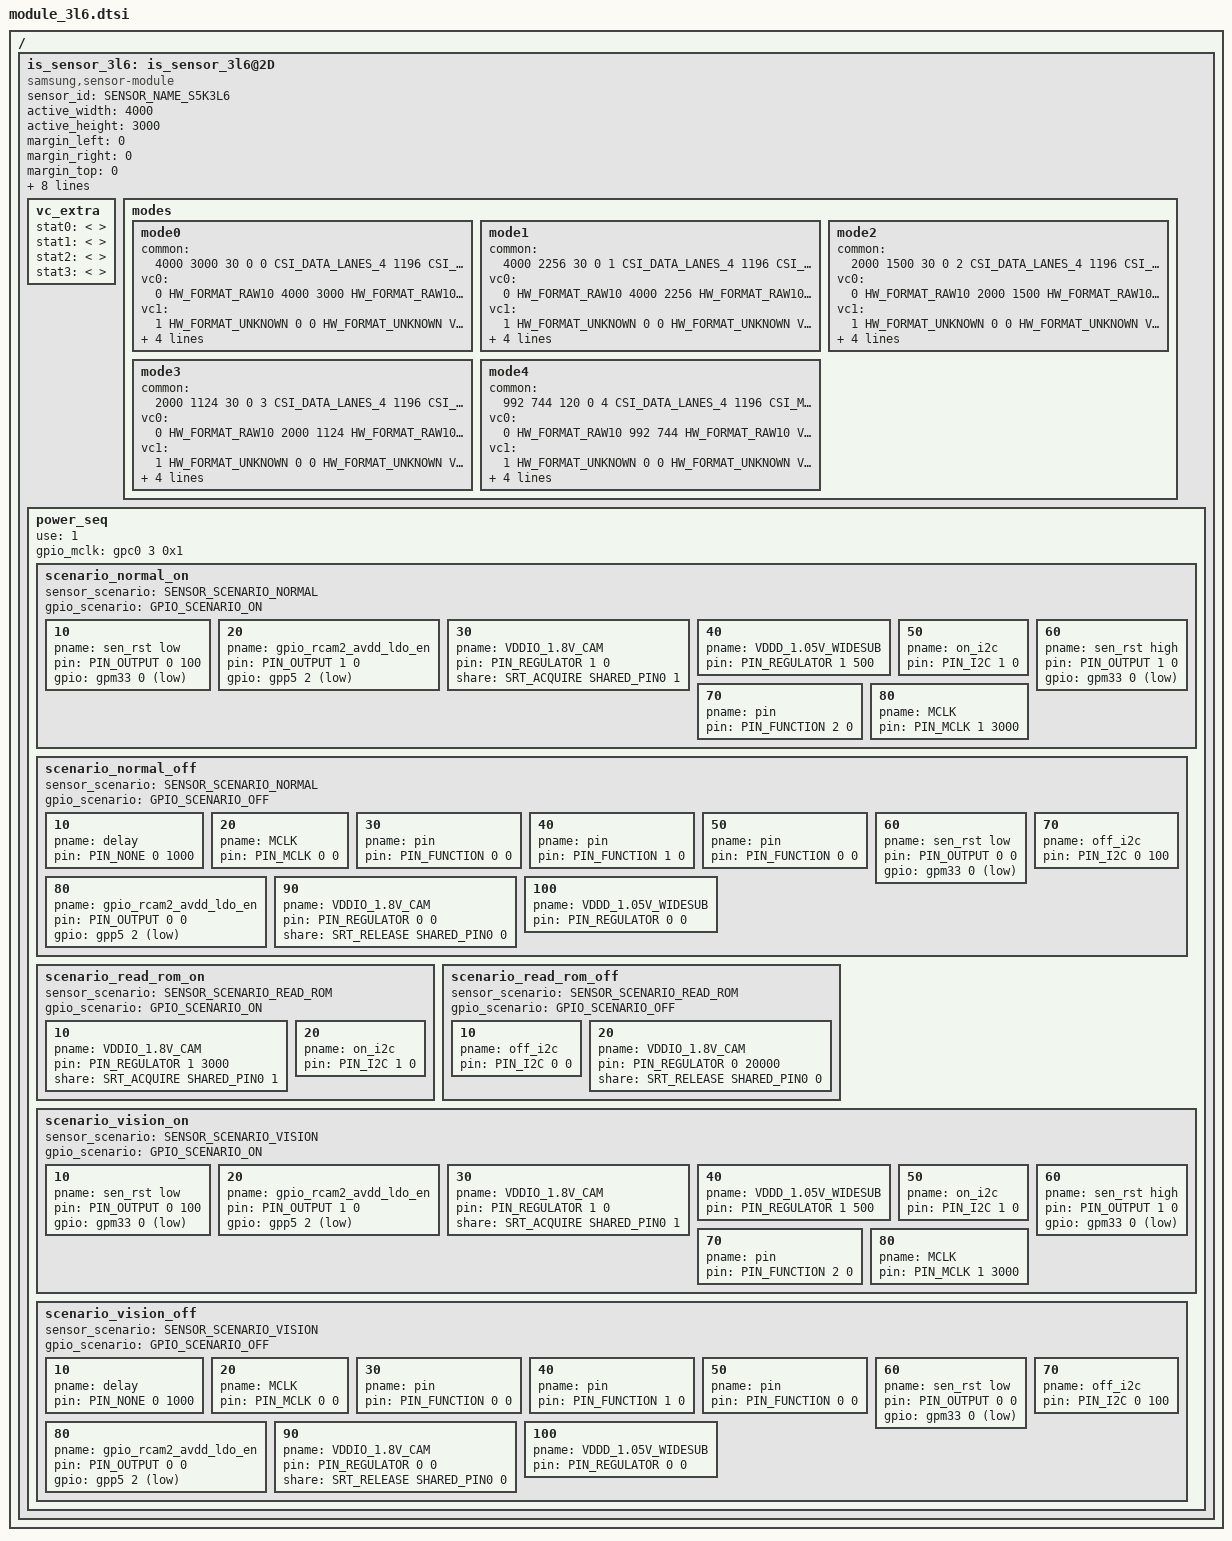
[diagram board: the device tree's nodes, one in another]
/*
 * SAMSUNG EXYNOSxxxx board camera device tree source
 *
 * Copyright (c) 2019 Samsung Electronics Co., Ltd.
 *		http://www.samsung.com
 *
 * This program is free software; you can redistribute it and/or modify
 * it under the terms of the GNU General Public License version 2 as
 * published by the Free Software Foundation.
 */

#include <dt-bindings/camera/exynos_is_dt.h>

/ {
	fragment@camera {
		target-path = "/";
		__overlay__ {
			is_sensor_3l6: is_sensor_3l6@2D {
				compatible = "samsung,sensor-module";

				/* common */
				sensor_id = <SENSOR_NAME_S5K3L6>;
				active_width = <4000>;
				active_height = <3000>;
				margin_left = <0>;
				margin_right = <0>;
				margin_top = <0>;
				margin_bottom = <0>;
				max_framerate = <120>;
				bitwidth = <10>;
				use_retention_mode = <SENSOR_RETENTION_UNSUPPORTED>;
				sensor_maker = "SLSI";
				sensor_name = "S5K3L6";
				setfile_name = "setfile_3l6.bin";

				status = "okay";

				vc_extra {
					/* ex) statX = <stat_type, sensor_mode, max_width, max_height, max_element> */
					stat0 = </* not avaliable */>;	/* VC_BUF_DATA_TYPE_SENSOR_STAT1 */
					stat1 = </* not avaliable */>;	/* VC_BUF_DATA_TYPE_GENERAL_STAT1 */
					stat2 = </* not avaliable */>;	/* VC_BUF_DATA_TYPE_SENSOR_STAT2 */
					stat3 = </* not avaliable */>;	/* VC_BUF_DATA_TYPE_GENERAL_STAT2 */
				};

				/* sensor modes */
				modes {
						/* common = <width, height, fps, settle, mode, lane, speed, interleave, lrte, pd_mode> */
						/* vcX = <map, hwformat, width, height, hwformat, type, width, height> */

					mode0 {
						common = <4000 3000 30 0 0 CSI_DATA_LANES_4 1196 CSI_MODE_VC_DT LRTE_DISABLE PD_NONE EX_NONE>;
						vc0 = </* in */ 0 HW_FORMAT_RAW10 4000 3000	/* out */ HW_FORMAT_RAW10 VC_NOTHING 0 0>;
						vc1 = </* in */ 1 HW_FORMAT_UNKNOWN 0 0		/* out */ HW_FORMAT_UNKNOWN VC_NOTHING 0 0>;
						vc2 = </* in */ 2 HW_FORMAT_UNKNOWN 0 0		/* out */ HW_FORMAT_UNKNOWN VC_NOTHING 0 0>;
						vc3 = </* in */ 3 HW_FORMAT_UNKNOWN 0 0		/* out */ HW_FORMAT_UNKNOWN VC_NOTHING 0 0>;
					};
					mode1 {
						common = <4000 2256 30 0 1 CSI_DATA_LANES_4 1196 CSI_MODE_VC_DT LRTE_DISABLE PD_NONE EX_NONE>;
						vc0 = </* in */ 0 HW_FORMAT_RAW10 4000 2256	/* out */ HW_FORMAT_RAW10 VC_NOTHING 0 0>;
						vc1 = </* in */ 1 HW_FORMAT_UNKNOWN 0 0		/* out */ HW_FORMAT_UNKNOWN VC_NOTHING 0 0>;
						vc2 = </* in */ 2 HW_FORMAT_UNKNOWN 0 0		/* out */ HW_FORMAT_UNKNOWN VC_NOTHING 0 0>;
						vc3 = </* in */ 3 HW_FORMAT_UNKNOWN 0 0		/* out */ HW_FORMAT_UNKNOWN VC_NOTHING 0 0>;
					};
					mode2 {
						common = <2000 1500 30 0 2 CSI_DATA_LANES_4 1196 CSI_MODE_VC_DT LRTE_DISABLE PD_NONE EX_NONE>;
						vc0 = </* in */ 0 HW_FORMAT_RAW10 2000 1500	/* out */ HW_FORMAT_RAW10 VC_NOTHING 0 0>;
						vc1 = </* in */ 1 HW_FORMAT_UNKNOWN 0 0		/* out */ HW_FORMAT_UNKNOWN VC_NOTHING 0 0>;
						vc2 = </* in */ 2 HW_FORMAT_UNKNOWN 0 0		/* out */ HW_FORMAT_UNKNOWN VC_NOTHING 0 0>;
						vc3 = </* in */ 3 HW_FORMAT_UNKNOWN 0 0		/* out */ HW_FORMAT_UNKNOWN VC_NOTHING 0 0>;
					};
					mode3 {
						common = <2000 1124 30 0 3 CSI_DATA_LANES_4 1196 CSI_MODE_VC_DT LRTE_DISABLE PD_NONE EX_NONE>;
						vc0 = </* in */ 0 HW_FORMAT_RAW10 2000 1124	/* out */ HW_FORMAT_RAW10 VC_NOTHING 0 0>;
						vc1 = </* in */ 1 HW_FORMAT_UNKNOWN 0 0		/* out */ HW_FORMAT_UNKNOWN VC_NOTHING 0 0>;
						vc2 = </* in */ 2 HW_FORMAT_UNKNOWN 0 0		/* out */ HW_FORMAT_UNKNOWN VC_NOTHING 0 0>;
						vc3 = </* in */ 3 HW_FORMAT_UNKNOWN 0 0		/* out */ HW_FORMAT_UNKNOWN VC_NOTHING 0 0>;
					};
					mode4 {
						common = <992 744 120 0 4 CSI_DATA_LANES_4 1196 CSI_MODE_VC_DT LRTE_DISABLE PD_NONE EX_NONE>;
						vc0 = </* in */ 0 HW_FORMAT_RAW10 992 744	/* out */ HW_FORMAT_RAW10 VC_NOTHING 0 0>;
						vc1 = </* in */ 1 HW_FORMAT_UNKNOWN 0 0		/* out */ HW_FORMAT_UNKNOWN VC_NOTHING 0 0>;
						vc2 = </* in */ 2 HW_FORMAT_UNKNOWN 0 0		/* out */ HW_FORMAT_UNKNOWN VC_NOTHING 0 0>;
						vc3 = </* in */ 3 HW_FORMAT_UNKNOWN 0 0		/* out */ HW_FORMAT_UNKNOWN VC_NOTHING 0 0>;
					};
				};

				power_seq {
					use = <1>;
					gpio_mclk = <&gpc0 3 0x1>;

					scenario_normal_on {
						sensor_scenario = <SENSOR_SCENARIO_NORMAL>;
						gpio_scenario = <GPIO_SCENARIO_ON>;

						/* A start node number should be over the 10 for reserved number 0~9. */
						/* pname = "name";		pin = <act value dealy voltage>;	gpio = <gpx# # 0x1>; */
						10 { pname = "sen_rst low";				pin = <PIN_OUTPUT 0 100>;		gpio = <&gpm33 0 0x1>;	};
						20 { pname = "gpio_rcam2_avdd_ldo_en";	pin = <PIN_OUTPUT 1 0>;		gpio = <&gpp5 2 0x1>;		};
						30 { pname = "VDDIO_1.8V_CAM";		pin = <PIN_REGULATOR 1 0>;	share = <SRT_ACQUIRE SHARED_PIN0 1>;	};
						40 { pname = "VDDD_1.05V_WIDESUB";	pin = <PIN_REGULATOR 1 500>;	};
						50 { pname = "on_i2c";					pin = <PIN_I2C 1 0>;			};
						60 { pname = "sen_rst high";			pin = <PIN_OUTPUT 1 0>;		gpio = <&gpm33 0 0x1>;	};
						70 { pname = "pin";					pin = <PIN_FUNCTION 2 0>;		};
						80 { pname = "MCLK";					pin = <PIN_MCLK 1 3000>;		};
					};

					scenario_normal_off {
						sensor_scenario = <SENSOR_SCENARIO_NORMAL>;
						gpio_scenario = <GPIO_SCENARIO_OFF>;

						/* A start node number should be over the 10 for reserved number 0~9. */
						/* pname = "name";		pin = <act value dealy voltage>;	gpio = <gpx# # 0x1>; */
						10 { pname = "delay";					pin = <PIN_NONE 0 1000>;				};
						20 { pname = "MCLK";					pin = <PIN_MCLK 0 0>;					};
						30 { pname = "pin";					pin = <PIN_FUNCTION 0 0>;				};
						40 { pname = "pin";					pin = <PIN_FUNCTION 1 0>;				};
						50 { pname = "pin";					pin = <PIN_FUNCTION 0 0>;				};
						60 { pname = "sen_rst low";				pin = <PIN_OUTPUT 0 0>;		gpio = <&gpm33 0 0x1>;	};
						70 { pname = "off_i2c";					pin = <PIN_I2C 0 100>;					};
						80 { pname = "gpio_rcam2_avdd_ldo_en";	pin = <PIN_OUTPUT 0 0>;		gpio = <&gpp5 2 0x1>;	};
						90 { pname = "VDDIO_1.8V_CAM";		pin = <PIN_REGULATOR 0 0>;	share = <SRT_RELEASE SHARED_PIN0 0>;	};
						100 { pname = "VDDD_1.05V_WIDESUB";	pin = <PIN_REGULATOR 0 0>;			};
					};

					scenario_read_rom_on {
						sensor_scenario = <SENSOR_SCENARIO_READ_ROM>;
						gpio_scenario = <GPIO_SCENARIO_ON>;

						/* A start node number should be over the 10 for reserved number 0~9. */
						/* pname = "name";		pin = <act value dealy voltage>;	gpio = <gpx# # 0x1>; */
						10 { pname = "VDDIO_1.8V_CAM";	pin = <PIN_REGULATOR 1 3000>;		share = <SRT_ACQUIRE SHARED_PIN0 1>;	};
						20 { pname = "on_i2c";					pin = <PIN_I2C 1 0>; 					};
					};

					scenario_read_rom_off {
						sensor_scenario = <SENSOR_SCENARIO_READ_ROM>;
						gpio_scenario = <GPIO_SCENARIO_OFF>;

						/* A start node number should be over the 10 for reserved number 0~9. */
						/* pname = "name";		pin = <act value dealy voltage>;	gpio = <gpx# # 0x1>; */
						10 { pname = "off_i2c";					pin = <PIN_I2C 0 0>;					};
						20 { pname = "VDDIO_1.8V_CAM";		pin = <PIN_REGULATOR 0 20000>;	share = <SRT_RELEASE SHARED_PIN0 0>;	};
					};

					scenario_vision_on {
						sensor_scenario = <SENSOR_SCENARIO_VISION>;
						gpio_scenario = <GPIO_SCENARIO_ON>;

						/* A start node number should be over the 10 for reserved number 0~9. */
						/* pname = "name";		pin = <act value dealy voltage>;	gpio = <gpx# # 0x1>; */
						10 { pname = "sen_rst low";				pin = <PIN_OUTPUT 0 100>;		gpio = <&gpm33 0 0x1>;	};
						20 { pname = "gpio_rcam2_avdd_ldo_en";	pin = <PIN_OUTPUT 1 0>;		gpio = <&gpp5 2 0x1>;		};
						30 { pname = "VDDIO_1.8V_CAM";		pin = <PIN_REGULATOR 1 0>;	share = <SRT_ACQUIRE SHARED_PIN0 1>;	};
						40 { pname = "VDDD_1.05V_WIDESUB";	pin = <PIN_REGULATOR 1 500>;	};
						50 { pname = "on_i2c";					pin = <PIN_I2C 1 0>;			};
						60 { pname = "sen_rst high";			pin = <PIN_OUTPUT 1 0>;		gpio = <&gpm33 0 0x1>;	};
						70 { pname = "pin";					pin = <PIN_FUNCTION 2 0>;		};
						80 { pname = "MCLK";					pin = <PIN_MCLK 1 3000>;		};
					};

					scenario_vision_off {
						sensor_scenario = <SENSOR_SCENARIO_VISION>;
						gpio_scenario = <GPIO_SCENARIO_OFF>;

						/* A start node number should be over the 10 for reserved number 0~9. */
						/* pname = "name";		pin = <act value dealy voltage>; 	gpio = <gpx# # 0x1>; */
						10 { pname = "delay";					pin = <PIN_NONE 0 1000>;				};
						20 { pname = "MCLK";					pin = <PIN_MCLK 0 0>;					};
						30 { pname = "pin";					pin = <PIN_FUNCTION 0 0>;				};
						40 { pname = "pin";					pin = <PIN_FUNCTION 1 0>;				};
						50 { pname = "pin";					pin = <PIN_FUNCTION 0 0>;				};
						60 { pname = "sen_rst low";				pin = <PIN_OUTPUT 0 0>;		gpio = <&gpm33 0 0x1>;	};
						70 { pname = "off_i2c";					pin = <PIN_I2C 0 100>;					};
						80 { pname = "gpio_rcam2_avdd_ldo_en";	pin = <PIN_OUTPUT 0 0>;		gpio = <&gpp5 2 0x1>;	};
						90 { pname = "VDDIO_1.8V_CAM";		pin = <PIN_REGULATOR 0 0>;	share = <SRT_RELEASE SHARED_PIN0 0>;	};
						100 { pname = "VDDD_1.05V_WIDESUB";	pin = <PIN_REGULATOR 0 0>;			};
					};
				};
			};
		}; /* end of __overlay__ */
	}; /* end of fragment */
}; /* end of root */
